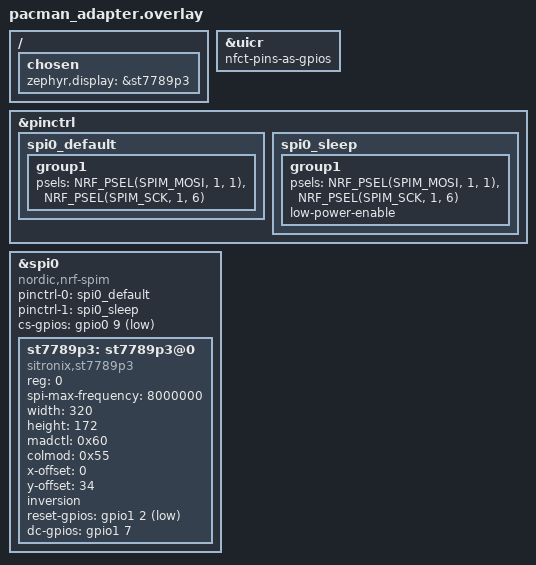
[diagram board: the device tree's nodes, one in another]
/ {
    chosen {
        /* zephyr,display is what both Zephyr's LVGL glue and ZMK's display
         * subsystem read; zmk,display is not a real chosen property in
         * current ZMK and was only ever a leftover alongside this one. */
        zephyr,display = &st7789p3;
    };
};

&uicr {
    /* CS pin (P0.09) defaults to the NFC antenna function on nRF52840;
     * this releases it for GPIO use. Replaces the removed
     * CONFIG_NFCT_PINS_AS_GPIOS Kconfig symbol (Zephyr 4.1+). */
    nfct-pins-as-gpios;
};

&pinctrl {
    spi0_default: spi0_default {
        group1 {
            psels = <NRF_PSEL(SPIM_MOSI, 1, 1)>,
                    <NRF_PSEL(SPIM_SCK, 1, 6)>;
        };
    };
    spi0_sleep: spi0_sleep {
        group1 {
            psels = <NRF_PSEL(SPIM_MOSI, 1, 1)>,
                    <NRF_PSEL(SPIM_SCK, 1, 6)>;
            low-power-enable;
        };
    };
};

&spi0 {
    compatible = "nordic,nrf-spim";
    status = "okay";
    pinctrl-0 = <&spi0_default>;
    pinctrl-1 = <&spi0_sleep>;
    pinctrl-names = "default", "sleep";
    cs-gpios = <&gpio0 9 GPIO_ACTIVE_LOW>;

    st7789p3: st7789p3@0 {
        compatible = "sitronix,st7789p3";
        reg = <0>;
        /* nRF52840 SPIM0/1/2 cap out at 8 MHz; only SPIM3 does 32 MHz. */
        spi-max-frequency = <8000000>;
        width = <320>;
        height = <172>;
        /* MV|MX for landscape. If the image is mirrored/upside-down on
         * actual hardware, try 0xA0 (MV|MY) or 0xE0 (MV|MX|MY) instead —
         * this can't be verified without hardware. */
        madctl = <0x60>;
        colmod = <0x55>;
        x-offset = <0>;
        y-offset = <34>;
        inversion;
        reset-gpios = <&gpio1 2 GPIO_ACTIVE_LOW>;
        dc-gpios = <&gpio1 7 GPIO_ACTIVE_HIGH>;
    };
};
